# ioam3358 register map
Registers are 32-bit, access not given, no defined reset value unless marked. A register's access mark holds for its fields unless they carry their own. Addresses are absolute; registers are grouped by the start of their names; [hi:lo] are bit positions.

## UART3
0x481A6000 UART3_DLL 8-bit
0x481A6000 UART3_RHR 8-bit
0x481A6000 UART3_THR 8-bit
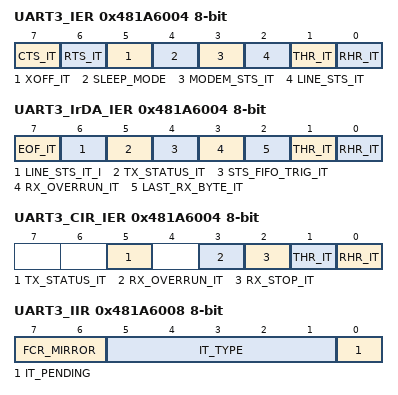
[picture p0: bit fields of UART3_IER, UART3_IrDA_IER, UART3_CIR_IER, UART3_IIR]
0x481A6004 UART3_IER 8-bit
  [7] CTS_IT, [6] RTS_IT, [5] XOFF_IT, [4] SLEEP_MODE, [3] MODEM_STS_IT, [2] LINE_STS_IT, [1] THR_IT, [0] RHR_IT
0x481A6004 UART3_DLH 8-bit
0x481A6004 UART3_IrDA_IER 8-bit
  [7] EOF_IT, [6] LINE_STS_IT_I, [5] TX_STATUS_IT, [4] STS_FIFO_TRIG_IT, [3] RX_OVERRUN_IT, [2] LAST_RX_BYTE_IT, [1] THR_IT, [0] RHR_IT
0x481A6004 UART3_CIR_IER 8-bit
  [5] TX_STATUS_IT, [3] RX_OVERRUN_IT, [2] RX_STOP_IT, [1] THR_IT, [0] RHR_IT
0x481A6008 UART3_IIR 8-bit
  [7:6] FCR_MIRROR, [5:1] IT_TYPE, [0] IT_PENDING
0x481A6008 UART3_FCR 8-bit
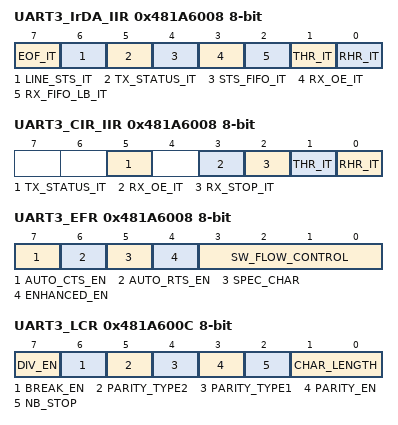
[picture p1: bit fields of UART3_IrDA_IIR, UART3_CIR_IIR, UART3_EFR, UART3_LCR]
0x481A6008 UART3_IrDA_IIR 8-bit
  [7] EOF_IT, [6] LINE_STS_IT, [5] TX_STATUS_IT, [4] STS_FIFO_IT, [3] RX_OE_IT, [2] RX_FIFO_LB_IT, [1] THR_IT, [0] RHR_IT
0x481A6008 UART3_CIR_IIR 8-bit
  [5] TX_STATUS_IT, [3] RX_OE_IT, [2] RX_STOP_IT, [1] THR_IT, [0] RHR_IT
0x481A6008 UART3_EFR 8-bit
  [7] AUTO_CTS_EN, [6] AUTO_RTS_EN, [5] SPEC_CHAR, [4] ENHANCED_EN, [3:0] SW_FLOW_CONTROL
0x481A600C UART3_LCR 8-bit
  [7] DIV_EN, [6] BREAK_EN, [5] PARITY_TYPE2, [4] PARITY_TYPE1, [3] PARITY_EN, [2] NB_STOP, [1:0] CHAR_LENGTH
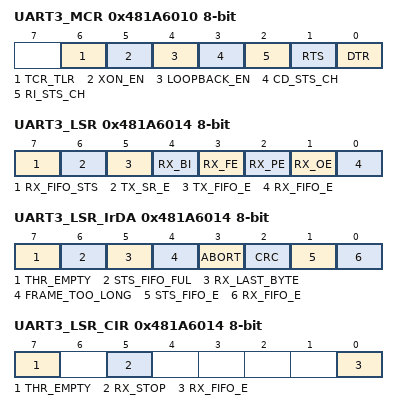
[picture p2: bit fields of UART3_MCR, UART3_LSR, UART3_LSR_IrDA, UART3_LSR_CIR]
0x481A6010 UART3_MCR 8-bit
  [6] TCR_TLR, [5] XON_EN, [4] LOOPBACK_EN, [3] CD_STS_CH, [2] RI_STS_CH, [1] RTS, [0] DTR
0x481A6010 UART3_XON1_ADDR1 8-bit
0x481A6014 UART3_LSR 8-bit
  [7] RX_FIFO_STS, [6] TX_SR_E, [5] TX_FIFO_E, [4] RX_BI, [3] RX_FE, [2] RX_PE, [1] RX_OE, [0] RX_FIFO_E
0x481A6014 UART3_XON2_ADDR2 8-bit
0x481A6014 UART3_LSR_IrDA 8-bit
  [7] THR_EMPTY, [6] STS_FIFO_FUL, [5] RX_LAST_BYTE, [4] FRAME_TOO_LONG, [3] ABORT, [2] CRC, [1] STS_FIFO_E, [0] RX_FIFO_E
0x481A6014 UART3_LSR_CIR 8-bit
  [7] THR_EMPTY, [5] RX_STOP, [0] RX_FIFO_E
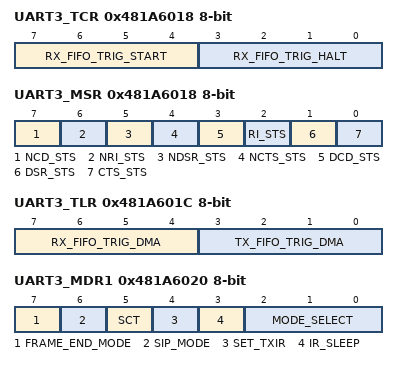
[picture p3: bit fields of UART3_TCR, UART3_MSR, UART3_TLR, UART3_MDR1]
0x481A6018 UART3_TCR 8-bit
  [7:4] RX_FIFO_TRIG_START, [3:0] RX_FIFO_TRIG_HALT
0x481A6018 UART3_XOFF1 8-bit
0x481A6018 UART3_MSR 8-bit
  [7] NCD_STS, [6] NRI_STS, [5] NDSR_STS, [4] NCTS_STS, [3] DCD_STS, [2] RI_STS, [1] DSR_STS, [0] CTS_STS
0x481A601C UART3_TLR 8-bit
  [7:4] RX_FIFO_TRIG_DMA, [3:0] TX_FIFO_TRIG_DMA
0x481A601C UART3_SPR 8-bit
0x481A601C UART3_XOFF2 8-bit
0x481A6020 UART3_MDR1 8-bit
  [7] FRAME_END_MODE, [6] SIP_MODE, [5] SCT, [4] SET_TXIR, [3] IR_SLEEP, [2:0] MODE_SELECT
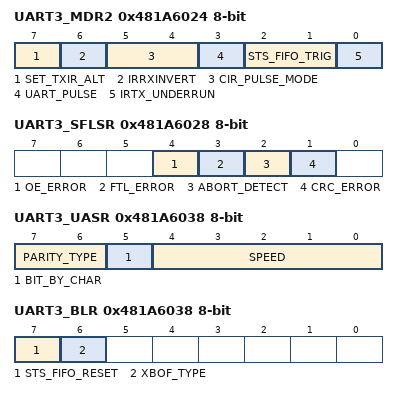
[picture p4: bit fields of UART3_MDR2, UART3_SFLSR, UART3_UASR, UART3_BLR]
0x481A6024 UART3_MDR2 8-bit
  [7] SET_TXIR_ALT, [6] IRRXINVERT, [5:4] CIR_PULSE_MODE, [3] UART_PULSE, [2:1] STS_FIFO_TRIG, [0] IRTX_UNDERRUN
0x481A6028 UART3_SFLSR 8-bit
  [4] OE_ERROR, [3] FTL_ERROR, [2] ABORT_DETECT, [1] CRC_ERROR
0x481A6028 UART3_TXFLL 8-bit
0x481A602C UART3_TXFLH 8-bit
  [4:0] TXFLH
0x481A602C UART3_RESUME 8-bit
0x481A6030 UART3_SFREGL 8-bit
0x481A6030 UART3_RXFLL 8-bit
0x481A6034 UART3_SFREGH 8-bit
  [3:0] SFREGH
0x481A6034 UART3_RXFLH 8-bit
  [3:0] RXFLH
0x481A6038 UART3_UASR 8-bit
  [7:6] PARITY_TYPE, [5] BIT_BY_CHAR, [4:0] SPEED
0x481A6038 UART3_BLR 8-bit
  [7] STS_FIFO_RESET, [6] XBOF_TYPE
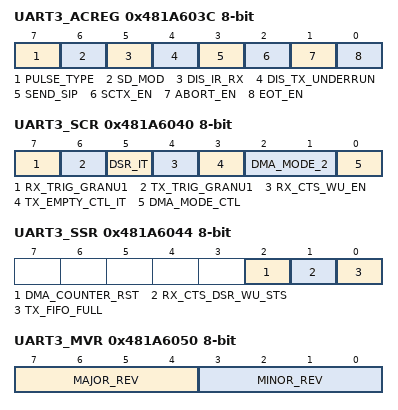
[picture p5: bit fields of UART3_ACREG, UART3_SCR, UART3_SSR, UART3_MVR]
0x481A603C UART3_ACREG 8-bit
  [7] PULSE_TYPE, [6] SD_MOD, [5] DIS_IR_RX, [4] DIS_TX_UNDERRUN, [3] SEND_SIP, [2] SCTX_EN, [1] ABORT_EN, [0] EOT_EN
0x481A6040 UART3_SCR 8-bit
  [7] RX_TRIG_GRANU1, [6] TX_TRIG_GRANU1, [5] DSR_IT, [4] RX_CTS_WU_EN, [3] TX_EMPTY_CTL_IT, [2:1] DMA_MODE_2, [0] DMA_MODE_CTL
0x481A6044 UART3_SSR 8-bit
  [2] DMA_COUNTER_RST, [1] RX_CTS_DSR_WU_STS, [0] TX_FIFO_FULL
0x481A6048 UART3_EBLR 8-bit
0x481A6050 UART3_MVR 8-bit
  [7:4] MAJOR_REV, [3:0] MINOR_REV
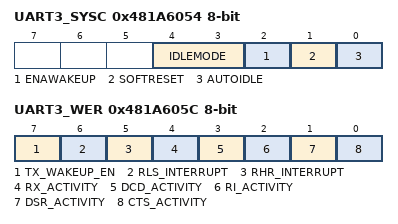
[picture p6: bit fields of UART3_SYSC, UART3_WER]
0x481A6054 UART3_SYSC 8-bit
  [4:3] IDLEMODE, [2] ENAWAKEUP, [1] SOFTRESET, [0] AUTOIDLE
0x481A6058 UART3_SYSS 8-bit
  [0] RESETDONE
0x481A605C UART3_WER 8-bit
  [7] TX_WAKEUP_EN, [6] RLS_INTERRUPT, [5] RHR_INTERRUPT, [4] RX_ACTIVITY, [3] DCD_ACTIVITY, [2] RI_ACTIVITY, [1] DSR_ACTIVITY, [0] CTS_ACTIVITY
0x481A6060 UART3_CFPS 8-bit

## UART4
0x481A8000 UART4_DLL 8-bit
0x481A8000 UART4_RHR 8-bit
0x481A8000 UART4_THR 8-bit
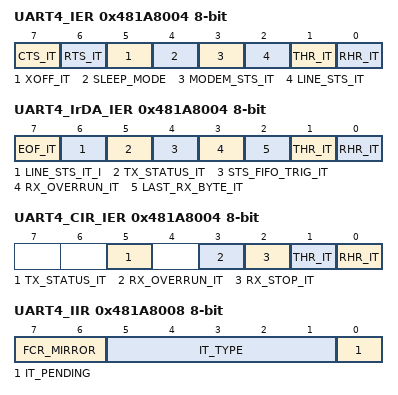
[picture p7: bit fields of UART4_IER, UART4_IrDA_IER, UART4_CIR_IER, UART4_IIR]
0x481A8004 UART4_IER 8-bit
  [7] CTS_IT, [6] RTS_IT, [5] XOFF_IT, [4] SLEEP_MODE, [3] MODEM_STS_IT, [2] LINE_STS_IT, [1] THR_IT, [0] RHR_IT
0x481A8004 UART4_DLH 8-bit
0x481A8004 UART4_IrDA_IER 8-bit
  [7] EOF_IT, [6] LINE_STS_IT_I, [5] TX_STATUS_IT, [4] STS_FIFO_TRIG_IT, [3] RX_OVERRUN_IT, [2] LAST_RX_BYTE_IT, [1] THR_IT, [0] RHR_IT
0x481A8004 UART4_CIR_IER 8-bit
  [5] TX_STATUS_IT, [3] RX_OVERRUN_IT, [2] RX_STOP_IT, [1] THR_IT, [0] RHR_IT
0x481A8008 UART4_IIR 8-bit
  [7:6] FCR_MIRROR, [5:1] IT_TYPE, [0] IT_PENDING
0x481A8008 UART4_FCR 8-bit
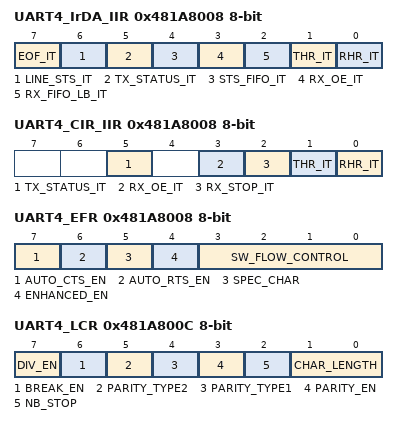
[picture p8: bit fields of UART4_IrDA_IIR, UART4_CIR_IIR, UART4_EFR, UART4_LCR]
0x481A8008 UART4_IrDA_IIR 8-bit
  [7] EOF_IT, [6] LINE_STS_IT, [5] TX_STATUS_IT, [4] STS_FIFO_IT, [3] RX_OE_IT, [2] RX_FIFO_LB_IT, [1] THR_IT, [0] RHR_IT
0x481A8008 UART4_CIR_IIR 8-bit
  [5] TX_STATUS_IT, [3] RX_OE_IT, [2] RX_STOP_IT, [1] THR_IT, [0] RHR_IT
0x481A8008 UART4_EFR 8-bit
  [7] AUTO_CTS_EN, [6] AUTO_RTS_EN, [5] SPEC_CHAR, [4] ENHANCED_EN, [3:0] SW_FLOW_CONTROL
0x481A800C UART4_LCR 8-bit
  [7] DIV_EN, [6] BREAK_EN, [5] PARITY_TYPE2, [4] PARITY_TYPE1, [3] PARITY_EN, [2] NB_STOP, [1:0] CHAR_LENGTH
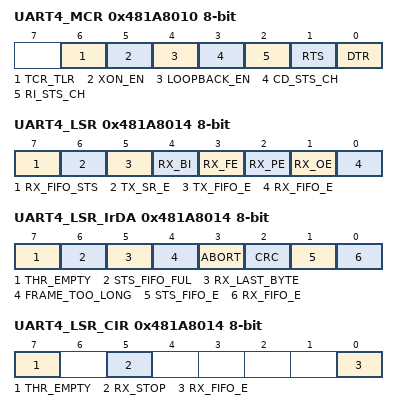
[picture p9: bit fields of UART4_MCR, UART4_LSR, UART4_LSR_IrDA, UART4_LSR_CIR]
0x481A8010 UART4_MCR 8-bit
  [6] TCR_TLR, [5] XON_EN, [4] LOOPBACK_EN, [3] CD_STS_CH, [2] RI_STS_CH, [1] RTS, [0] DTR
0x481A8010 UART4_XON1_ADDR1 8-bit
0x481A8014 UART4_LSR 8-bit
  [7] RX_FIFO_STS, [6] TX_SR_E, [5] TX_FIFO_E, [4] RX_BI, [3] RX_FE, [2] RX_PE, [1] RX_OE, [0] RX_FIFO_E
0x481A8014 UART4_XON2_ADDR2 8-bit
0x481A8014 UART4_LSR_IrDA 8-bit
  [7] THR_EMPTY, [6] STS_FIFO_FUL, [5] RX_LAST_BYTE, [4] FRAME_TOO_LONG, [3] ABORT, [2] CRC, [1] STS_FIFO_E, [0] RX_FIFO_E
0x481A8014 UART4_LSR_CIR 8-bit
  [7] THR_EMPTY, [5] RX_STOP, [0] RX_FIFO_E
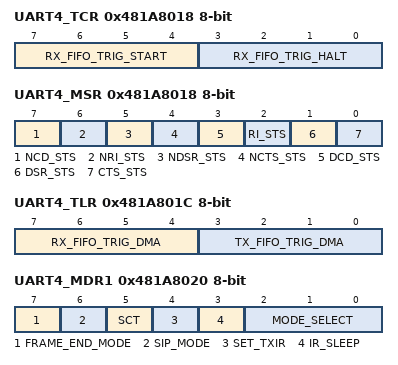
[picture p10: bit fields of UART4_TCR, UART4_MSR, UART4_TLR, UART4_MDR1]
0x481A8018 UART4_TCR 8-bit
  [7:4] RX_FIFO_TRIG_START, [3:0] RX_FIFO_TRIG_HALT
0x481A8018 UART4_XOFF1 8-bit
0x481A8018 UART4_MSR 8-bit
  [7] NCD_STS, [6] NRI_STS, [5] NDSR_STS, [4] NCTS_STS, [3] DCD_STS, [2] RI_STS, [1] DSR_STS, [0] CTS_STS
0x481A801C UART4_TLR 8-bit
  [7:4] RX_FIFO_TRIG_DMA, [3:0] TX_FIFO_TRIG_DMA
0x481A801C UART4_SPR 8-bit
0x481A801C UART4_XOFF2 8-bit
0x481A8020 UART4_MDR1 8-bit
  [7] FRAME_END_MODE, [6] SIP_MODE, [5] SCT, [4] SET_TXIR, [3] IR_SLEEP, [2:0] MODE_SELECT
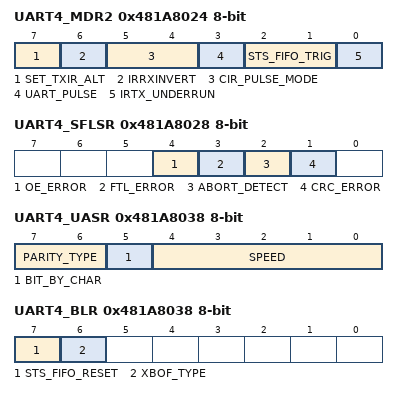
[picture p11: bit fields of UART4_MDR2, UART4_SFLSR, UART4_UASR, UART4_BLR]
0x481A8024 UART4_MDR2 8-bit
  [7] SET_TXIR_ALT, [6] IRRXINVERT, [5:4] CIR_PULSE_MODE, [3] UART_PULSE, [2:1] STS_FIFO_TRIG, [0] IRTX_UNDERRUN
0x481A8028 UART4_SFLSR 8-bit
  [4] OE_ERROR, [3] FTL_ERROR, [2] ABORT_DETECT, [1] CRC_ERROR
0x481A8028 UART4_TXFLL 8-bit
0x481A802C UART4_TXFLH 8-bit
  [4:0] TXFLH
0x481A802C UART4_RESUME 8-bit
0x481A8030 UART4_SFREGL 8-bit
0x481A8030 UART4_RXFLL 8-bit
0x481A8034 UART4_SFREGH 8-bit
  [3:0] SFREGH
0x481A8034 UART4_RXFLH 8-bit
  [3:0] RXFLH
0x481A8038 UART4_UASR 8-bit
  [7:6] PARITY_TYPE, [5] BIT_BY_CHAR, [4:0] SPEED
0x481A8038 UART4_BLR 8-bit
  [7] STS_FIFO_RESET, [6] XBOF_TYPE
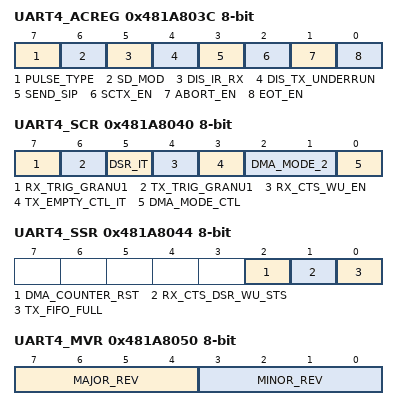
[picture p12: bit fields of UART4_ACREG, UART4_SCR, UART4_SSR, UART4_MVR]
0x481A803C UART4_ACREG 8-bit
  [7] PULSE_TYPE, [6] SD_MOD, [5] DIS_IR_RX, [4] DIS_TX_UNDERRUN, [3] SEND_SIP, [2] SCTX_EN, [1] ABORT_EN, [0] EOT_EN
0x481A8040 UART4_SCR 8-bit
  [7] RX_TRIG_GRANU1, [6] TX_TRIG_GRANU1, [5] DSR_IT, [4] RX_CTS_WU_EN, [3] TX_EMPTY_CTL_IT, [2:1] DMA_MODE_2, [0] DMA_MODE_CTL
0x481A8044 UART4_SSR 8-bit
  [2] DMA_COUNTER_RST, [1] RX_CTS_DSR_WU_STS, [0] TX_FIFO_FULL
0x481A8048 UART4_EBLR 8-bit
0x481A8050 UART4_MVR 8-bit
  [7:4] MAJOR_REV, [3:0] MINOR_REV
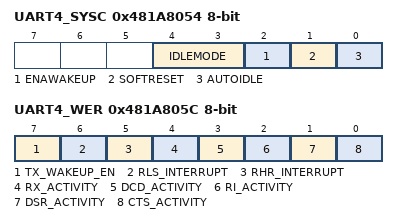
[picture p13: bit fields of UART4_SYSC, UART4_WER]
0x481A8054 UART4_SYSC 8-bit
  [4:3] IDLEMODE, [2] ENAWAKEUP, [1] SOFTRESET, [0] AUTOIDLE
0x481A8058 UART4_SYSS 8-bit
  [0] RESETDONE
0x481A805C UART4_WER 8-bit
  [7] TX_WAKEUP_EN, [6] RLS_INTERRUPT, [5] RHR_INTERRUPT, [4] RX_ACTIVITY, [3] DCD_ACTIVITY, [2] RI_ACTIVITY, [1] DSR_ACTIVITY, [0] CTS_ACTIVITY
0x481A8060 UART4_CFPS 8-bit
